# MIMXRT685S_cm33 register map
Vendor: nxp.com; File version: 1.0
CPU: CM33 r2p0, little endian, MPU, FPU, VTOR, 3 interrupt priority bits
Registers are 32-bit, read-write, reset 0x0 unless marked. A register's access mark holds for its fields unless they carry their own. Offsets are from the block's base; [hi:lo] are bit positions; {n}, {i} and the like mark numbered series.

## UTICK0 — LPC-Next0 Micro-tick Timer (UTICK)
Base 0x4000F000
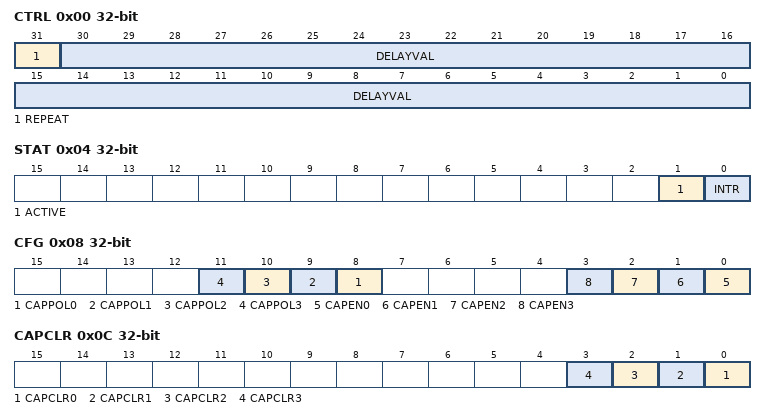
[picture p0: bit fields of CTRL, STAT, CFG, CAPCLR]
0x00 CTRL — Control register.
  [31] REPEAT — Repeat delay. 0 = One-time delay. 1 = Delay repeats continuously.
  [30:0] DELAYVAL — Tick interval value. The delay will be equal to DELAYVAL + 1 periods of the timer clock. The minimum usable value is 1, for a delay of 2 timer clocks. A value of 0 stops the timer.
0x04 STAT — Status register.
  [1] ACTIVE — Active flag. 0 = The Micro-Tick Timer is stopped. 1 = The Micro-Tick Timer is currently active.
  [0] INTR — Interrupt flag. 0 = No interrupt is pending. 1 = An interrupt is pending. A write of any value to this register clears this flag.
0x08 CFG — Capture configuration register.
  [n+8] CAPPOL{n} (n=0..3) — Capture Polarity {n}. 0 = Positive edge capture, 1 = Negative edge capture.
  [n] CAPEN{n} (n=0..3) — Enable Capture {n}. 1 = Enabled, 0 = Disabled.
0x0C CAPCLR wo reset not defined — Capture clear register.
  [n] CAPCLR{n} (n=0..3) — Clear capture {n}. Writing 1 to this bit clears the CAP{n} register value.
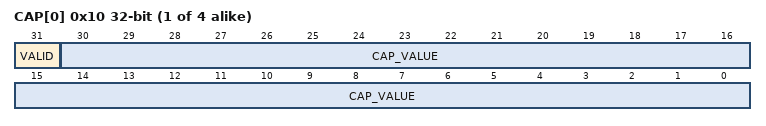
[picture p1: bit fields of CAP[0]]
{0x10+4i} CAP[{i}] (i=0..3) ro — Capture register .
  [31] VALID — Capture Valid. When 1, a value has been captured based on a transition of the related UTICK_CAPn pin. Cleared by writing to the related bit in the CAPCLR register.
  [30:0] CAP_VALUE — Capture value for the related capture event (UTICK_CAPn. Note: the value is 1 lower than the actual value of the Micro-tick Timer at the moment of the capture event.

## SYSCTL1 — system ccontroller 1
Base 0x40022000
0x10 MCLKPINDIR — mclk direction control
  [0] MCLKPINDIR — Selects one of the M33 interrupt sources
    0=INPUT_DIRECTION (MCLK is in input direction.); 1=OUTPUT_DIRECTION (MCLK is in the output direction.)
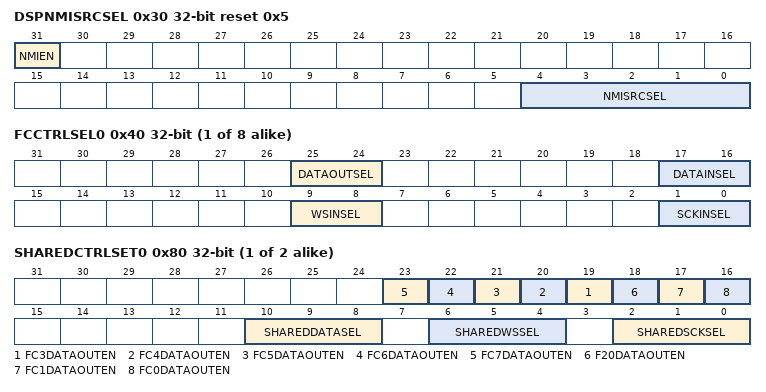
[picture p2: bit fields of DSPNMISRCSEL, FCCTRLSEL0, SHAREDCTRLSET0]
0x30 DSPNMISRCSEL reset 0x5 — DSP NMI source selection
  [31] NMIEN — NMI interrupt enable
    0=DISABLED (Disable NMI Interrupt); 1=ENABLED (Enable NMI Interrupt.)
  [4:0] NMISRCSEL — Selects one of the DSP interrupt sources as the NMI source. See DSP Interrupt Slot Table for Interrupt Slot Numers.
{0x40+4i} FCCTRLSEL{i} (i=0..7) — flexcomm control selection N
  [all] fields
    0=ORIG_FLEX_I2S_SIGNALS (Original FLEXCOMM I2S signals); 1=SHARED_SET0_I2S_SIGNALS; 2=SHARED_SET1_I2S_SIGNALS
  [25:24] DATAOUTSEL — DATA OUT Select. . .
  [17:16] DATAINSEL — DATA IN Select. . .
  [9:8] WSINSEL — WS IN Select. . .
  [1:0] SCKINSEL — SCK IN Select. . .
{0x80+4i} SHAREDCTRLSET{i} (i=0..1) — shared control set N
  [n+16] FC{n}DATAOUTEN (n=3..7) — FLEXCOMM{n} DATAOUT OUTPUT ENABLE
    0=INPUT; 1=OUTPUT
  [18] F20DATAOUTEN — FLEXCOMM2 DATAOUT OUTPUT ENABLE
    0=INPUT; 1=OUTPUT
  [17] FC1DATAOUTEN — FLEXCOMM1 DATAOUT OUTPUT ENABLE
    0=INPUT; 1=OUTPUT
  [16] FC0DATAOUTEN — FLEXCOMM0 DATAOUT OUTPUT ENABLE
    0=INPUT; 1=OUTPUT
  [10:8] SHAREDDATASEL — Shared DATA Select. . .
    {v}=FLEXCOMM{v} (v=0..7)
  [6:4] SHAREDWSSEL — Shared WS Select. . .
    {v}=FLEXCOMM{v} (v=0..7)
  [2:0] SHAREDSCKSEL — Shared SCK Select. . .
    {v}=FLEXCOMM{v} (v=0..7)
0x200 RXEVPULSEGEN — RX Event Pulse Generator
  [0] RXEVPULSEGEN — RX Event Pulse Generator. Writing a '1' to this register will create a one PSCLK pulse width of logic '1'. It is automatically cleared.
    0=NO_EFFECT; 1=PULSE_RXEV_HIGH (Pulse RXEV High for one PSCLK cycle.)

## FREQME — LPC_Next0 Frequency Measurement (FREQME)
Base 0x4002F000
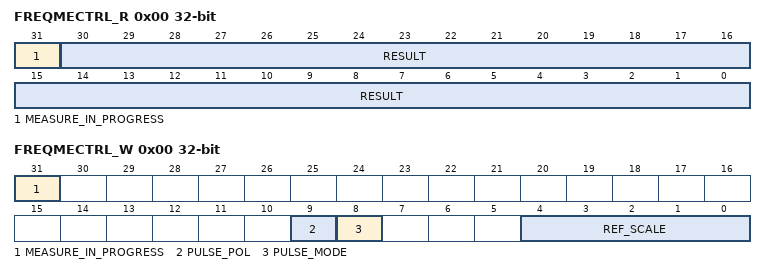
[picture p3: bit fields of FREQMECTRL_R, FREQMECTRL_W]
0x00 FREQMECTRL_R ro (FREQME view) — Frequency Measurement (in Read mode)
  [31] MEASURE_IN_PROGRESS
    0=CYCLE_DONE (Process complete. Measurement cycle is complete. The results are ready in the RESULT field.); 1=IN_PROGRESS (In Progress. Measurement cycle is in progress.)
  [30:0] RESULT
0x00 FREQMECTRL_W wo (FREQME view) — Freqeuncy Measurement (in Write mode)
  [31] MEASURE_IN_PROGRESS
    0=FORCE_TERMINATE (Force Terminate. Forces the termination of any measurement cycle currently in progress and resets RESULT or just resets RESULT if in idle.); 1=INITIATE_A_FREQME_CYCLE (Initiates Measurement Cycle. Initiates frequency or pulse width measurement process. Hardware clears the MEASURE_IN_PROGRESS bit when the measurement cycle completes. A new measurement starts if there is an active measurement in progress.)
  [9] PULSE_POL — Pulse Polarity
    0=HIGH_PERIOD (High Period. High period of reference clock is measured in Pulse Width Measurement mode triggered by the rising edge on the reference clock input.); 1=LOW_PERIOD (Low Period. Low period of reference clock is measured in Pulse Width Measurement mode triggered by the falling edge on the reference clock input.)
  [8] PULSE_MODE — Pulse Width Measurement mode select
    0=FREQ_ME_MODE (Frequency Measurement Mode. FREQMECTRL works in a Frequency Measurement mode. Once the measurement starts (real count start is aligned at rising edge arrival on reference clock), the target counter increments by the target clock until the reference counter running by the reference clock reaches the count end point selected by REF_SCALE.); 1=PULSE_ME_MODE (Pulse Width Measurement mode. FREQMECTRL works in a Pulse Width Measurement mode, measuring the high or low period of reference clock input selected by PULSE_POL. The target counter starts incrementing by the target clock once a corresponding trigger edge (rising edge for high period measurement and falling edge for low period) occurs.)
  [4:0] REF_SCALE — Reference Clock Scaling Factor
    0=COUNTCYCLE_1 (Count cycle = 2^0 = 1); 1=COUNTCYCLE_2 (Count cycle = 2^1 = 2); 2=COUNTCYCLE_4 (Count cycle = 2^4 = 4); 31=COUNTCYCLE_31 (Count cycle = 2^31 = 2,147,483,648)
